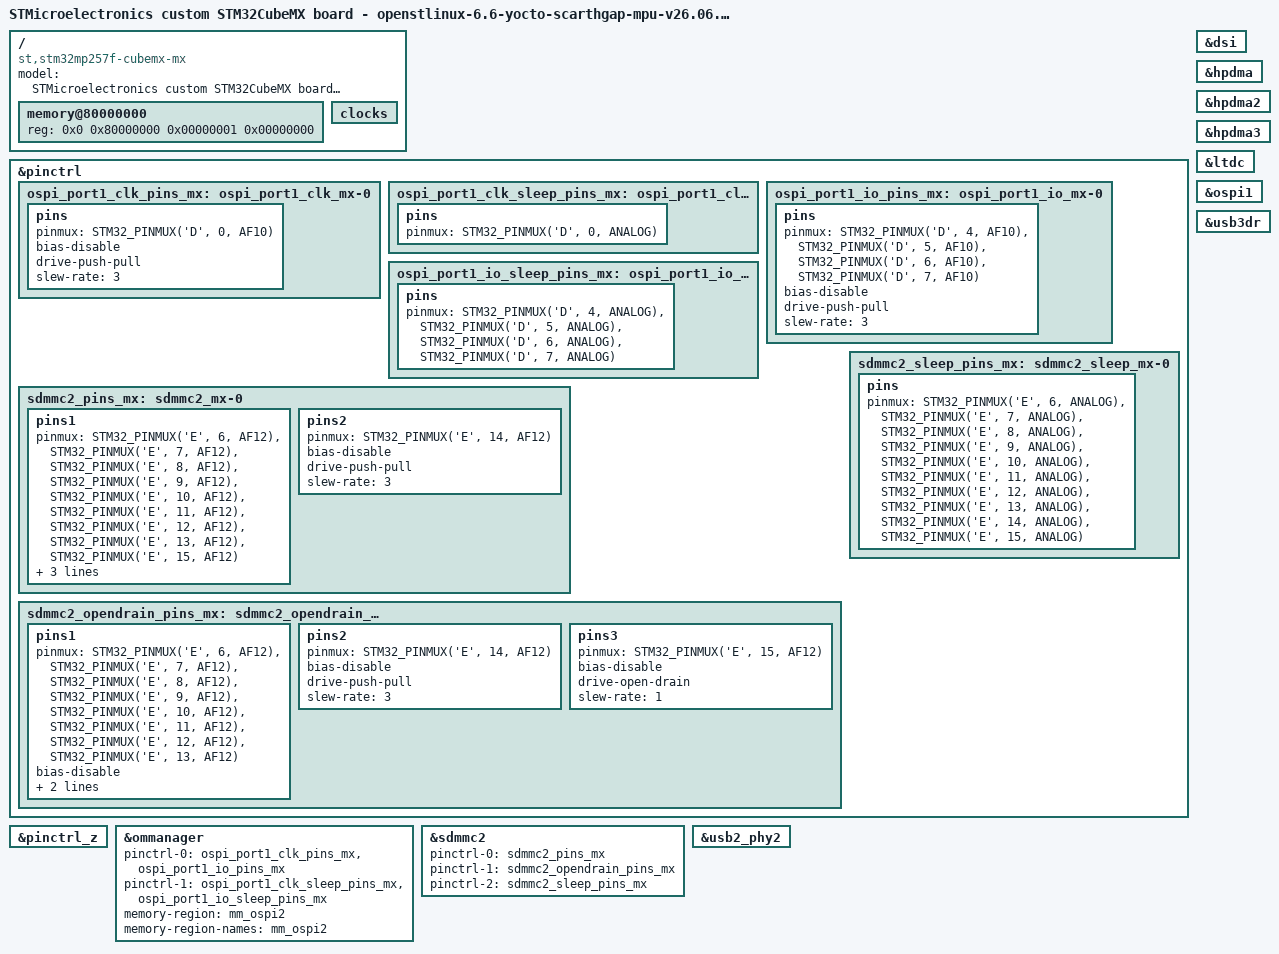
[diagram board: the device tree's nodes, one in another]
// SPDX-License-Identifier: (GPL-2.0-only OR BSD-3-Clause)
/*
 * Copyright (C) 2026, STMicroelectronics - All Rights Reserved
 * Author: STM32CubeMX code generation for STMicroelectronics.
 */

/* For more information on Device Tree configuration, please refer to
 * https://wiki.st.com/stm32mpu/wiki/Category:Device_tree_configuration
 */

/dts-v1/;

#include <dt-bindings/pinctrl/stm32-pinfunc.h>
#include "stm32mp257.dtsi"
#include "stm32mp25xf.dtsi"
#include "stm32mp257f-cubemx-mx-resmem.dtsi"
#include "stm32mp25xxai-pinctrl.dtsi"

/* USER CODE BEGIN includes */
/* USER CODE END includes */

/ {
	model = "STMicroelectronics custom STM32CubeMX board - openstlinux-6.6-yocto-scarthgap-mpu-v26.06.10";
	compatible = "st,stm32mp257f-cubemx-mx", "st,stm32mp257";

	memory@80000000 {
		device_type = "memory";
		reg = <0x0 0x80000000 0x00000001 0x00000000>;

		/* USER CODE BEGIN memory */
		/* USER CODE END memory */
	};

	/* USER CODE BEGIN root */
	/* USER CODE END root */

	clocks{

		/* USER CODE BEGIN clocks */
		/* USER CODE END clocks */
	};

}; /*root*/

&pinctrl {

	ospi_port1_clk_pins_mx: ospi_port1_clk_mx-0 {
		pins {
			pinmux = <STM32_PINMUX('D', 0, AF10)>; /* OCTOSPIM_P1_CLK */
			bias-disable;
			drive-push-pull;
			slew-rate = <3>;
		};
	};

	ospi_port1_clk_sleep_pins_mx: ospi_port1_clk_sleep_mx-0 {
		pins {
			pinmux = <STM32_PINMUX('D', 0, ANALOG)>; /* OCTOSPIM_P1_CLK */
		};
	};

	ospi_port1_io_pins_mx: ospi_port1_io_mx-0 {
		pins {
			pinmux = <STM32_PINMUX('D', 4, AF10)>, /* OCTOSPIM_P1_IO0 */
					 <STM32_PINMUX('D', 5, AF10)>, /* OCTOSPIM_P1_IO1 */
					 <STM32_PINMUX('D', 6, AF10)>, /* OCTOSPIM_P1_IO2 */
					 <STM32_PINMUX('D', 7, AF10)>; /* OCTOSPIM_P1_IO3 */
			bias-disable;
			drive-push-pull;
			slew-rate = <3>;
		};
	};

	ospi_port1_io_sleep_pins_mx: ospi_port1_io_sleep_mx-0 {
		pins {
			pinmux = <STM32_PINMUX('D', 4, ANALOG)>, /* OCTOSPIM_P1_IO0 */
					 <STM32_PINMUX('D', 5, ANALOG)>, /* OCTOSPIM_P1_IO1 */
					 <STM32_PINMUX('D', 6, ANALOG)>, /* OCTOSPIM_P1_IO2 */
					 <STM32_PINMUX('D', 7, ANALOG)>; /* OCTOSPIM_P1_IO3 */
		};
	};

	sdmmc2_pins_mx: sdmmc2_mx-0 {
		pins1 {
			pinmux = <STM32_PINMUX('E', 6, AF12)>, /* SDMMC2_D6 */
					 <STM32_PINMUX('E', 7, AF12)>, /* SDMMC2_D7 */
					 <STM32_PINMUX('E', 8, AF12)>, /* SDMMC2_D2 */
					 <STM32_PINMUX('E', 9, AF12)>, /* SDMMC2_D5 */
					 <STM32_PINMUX('E', 10, AF12)>, /* SDMMC2_D4 */
					 <STM32_PINMUX('E', 11, AF12)>, /* SDMMC2_D1 */
					 <STM32_PINMUX('E', 12, AF12)>, /* SDMMC2_D3 */
					 <STM32_PINMUX('E', 13, AF12)>, /* SDMMC2_D0 */
					 <STM32_PINMUX('E', 15, AF12)>; /* SDMMC2_CMD */
			bias-disable;
			drive-push-pull;
			slew-rate = <1>;
		};
		pins2 {
			pinmux = <STM32_PINMUX('E', 14, AF12)>; /* SDMMC2_CK */
			bias-disable;
			drive-push-pull;
			slew-rate = <3>;
		};
	};

	sdmmc2_opendrain_pins_mx: sdmmc2_opendrain_mx-0 {
		pins1 {
			pinmux = <STM32_PINMUX('E', 6, AF12)>, /* SDMMC2_D6 */
					 <STM32_PINMUX('E', 7, AF12)>, /* SDMMC2_D7 */
					 <STM32_PINMUX('E', 8, AF12)>, /* SDMMC2_D2 */
					 <STM32_PINMUX('E', 9, AF12)>, /* SDMMC2_D5 */
					 <STM32_PINMUX('E', 10, AF12)>, /* SDMMC2_D4 */
					 <STM32_PINMUX('E', 11, AF12)>, /* SDMMC2_D1 */
					 <STM32_PINMUX('E', 12, AF12)>, /* SDMMC2_D3 */
					 <STM32_PINMUX('E', 13, AF12)>; /* SDMMC2_D0 */
			bias-disable;
			drive-push-pull;
			slew-rate = <1>;
		};
		pins2 {
			pinmux = <STM32_PINMUX('E', 14, AF12)>; /* SDMMC2_CK */
			bias-disable;
			drive-push-pull;
			slew-rate = <3>;
		};
		pins3 {
			pinmux = <STM32_PINMUX('E', 15, AF12)>; /* SDMMC2_CMD */
			bias-disable;
			drive-open-drain;
			slew-rate = <1>;
		};
	};

	sdmmc2_sleep_pins_mx: sdmmc2_sleep_mx-0 {
		pins {
			pinmux = <STM32_PINMUX('E', 6, ANALOG)>, /* SDMMC2_D6 */
					 <STM32_PINMUX('E', 7, ANALOG)>, /* SDMMC2_D7 */
					 <STM32_PINMUX('E', 8, ANALOG)>, /* SDMMC2_D2 */
					 <STM32_PINMUX('E', 9, ANALOG)>, /* SDMMC2_D5 */
					 <STM32_PINMUX('E', 10, ANALOG)>, /* SDMMC2_D4 */
					 <STM32_PINMUX('E', 11, ANALOG)>, /* SDMMC2_D1 */
					 <STM32_PINMUX('E', 12, ANALOG)>, /* SDMMC2_D3 */
					 <STM32_PINMUX('E', 13, ANALOG)>, /* SDMMC2_D0 */
					 <STM32_PINMUX('E', 14, ANALOG)>, /* SDMMC2_CK */
					 <STM32_PINMUX('E', 15, ANALOG)>; /* SDMMC2_CMD */
		};
	};

	/* USER CODE BEGIN pinctrl */
	/* USER CODE END pinctrl */
};

&pinctrl_z {

	/* USER CODE BEGIN pinctrl_z */
	/* USER CODE END pinctrl_z */
};

&dsi {
	status = "okay";

	/* USER CODE BEGIN dsi */
	/* USER CODE END dsi */
};

&hpdma {
	status = "okay";

	/* USER CODE BEGIN hpdma */
	/* USER CODE END hpdma */
};

&hpdma2 {
	status = "okay";

	/* USER CODE BEGIN hpdma2 */
	/* USER CODE END hpdma2 */
};

&hpdma3 {
	status = "okay";

	/* USER CODE BEGIN hpdma3 */
	/* USER CODE END hpdma3 */
};

&ltdc {
	status = "okay";

	/* USER CODE BEGIN ltdc */
	/* USER CODE END ltdc */
};

&ommanager {
	pinctrl-names = "default", "sleep";
	pinctrl-0 = <&ospi_port1_clk_pins_mx>, <&ospi_port1_io_pins_mx>;
	pinctrl-1 = <&ospi_port1_clk_sleep_pins_mx>, <&ospi_port1_io_sleep_pins_mx>;
	status = "okay";
	memory-region = <&mm_ospi2>;
	memory-region-names = "mm_ospi2";

	/* USER CODE BEGIN ommanager */
	/* USER CODE END ommanager */
};

&ospi1 {
	status = "okay";

	/* USER CODE BEGIN ospi1 */
	/* USER CODE END ospi1 */
};

&sdmmc2 {
	pinctrl-names = "default", "opendrain", "sleep";
	pinctrl-0 = <&sdmmc2_pins_mx>;
	pinctrl-1 = <&sdmmc2_opendrain_pins_mx>;
	pinctrl-2 = <&sdmmc2_sleep_pins_mx>;
	status = "okay";

	/* USER CODE BEGIN sdmmc2 */
	/* USER CODE END sdmmc2 */
};

&usb2_phy2 {
	status = "okay";

	/* USER CODE BEGIN usb2_phy2 */
	/* USER CODE END usb2_phy2 */
};

&usb3dr {
	status = "okay";

	/* USER CODE BEGIN usb3dr */
	/* USER CODE END usb3dr */
};

/* USER CODE BEGIN addons */
/* USER CODE END addons */

